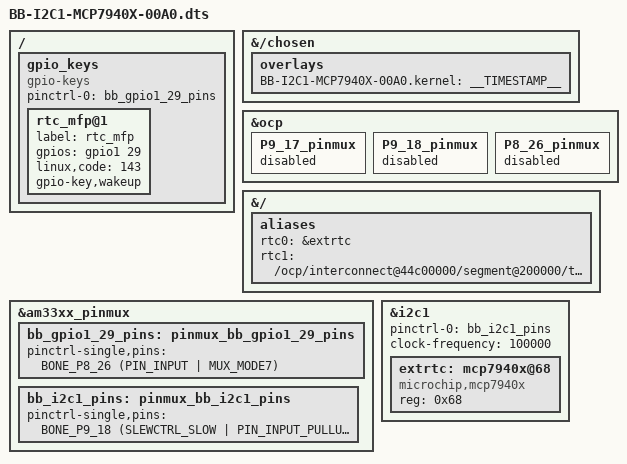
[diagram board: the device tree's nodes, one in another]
// SPDX-License-Identifier: GPL-2.0-only
/*
 * Copyright (C) 2015 Robert Nelson <robertcnelson@gmail.com>
 */

/dts-v1/;
/plugin/;

#include <dt-bindings/board/am335x-bbw-bbb-base.h>
#include <dt-bindings/pinctrl/am33xx.h>
#include <dt-bindings/gpio/gpio.h>

/*
 * Helper to show loaded overlays under: /proc/device-tree/chosen/overlays/
 */
&{/chosen} {
	overlays {
		BB-I2C1-MCP7940X-00A0.kernel = __TIMESTAMP__;
	};
};

/*
 * Free up the pins used by the cape from the pinmux helpers.
 */
&ocp {
	P9_17_pinmux { status = "disabled"; };	/* spi0_d1.i2c1_sda */
	P9_18_pinmux { status = "disabled"; };	/* spi0_cs0.i2c1_scl */
	P8_26_pinmux { status = "disabled"; };	/* rtc: gpio1_29 */
};

&{/} {
	aliases {
		rtc0 = &extrtc;
		/* find /sys/firmware/devicetree/ | grep rtc@ */
		rtc1 = "/ocp/interconnect@44c00000/segment@200000/target-module@3e000/rtc@0";
	};
};

/ {
	fragment@3 {
		target = <&am33xx_pinmux>;
		__overlay__ {

			bb_gpio1_29_pins: pinmux_bb_gpio1_29_pins {
				pinctrl-single,pins = <
					BONE_P8_26 (PIN_INPUT | MUX_MODE7) /* gpmc_csn0.gpio1_29 */
				>;
			};

			bb_i2c1_pins: pinmux_bb_i2c1_pins {
				pinctrl-single,pins = <
					BONE_P9_18 (SLEWCTRL_SLOW | PIN_INPUT_PULLUP | MUX_MODE2) /* spi0_d1.i2c1_sda */
					BONE_P9_17 (SLEWCTRL_SLOW | PIN_INPUT_PULLUP | MUX_MODE2) /* spi0_cs0.i2c1_scl */
				>;
			};
		};
	};

	fragment@4 {
		target-path="/";
		__overlay__ {

			gpio_keys {
				compatible = "gpio-keys";
				pinctrl-names = "default";
				pinctrl-0 = <&bb_gpio1_29_pins>;

				rtc_mfp@1 {
					label = "rtc_mfp";
					gpios = <&gpio1 29 GPIO_ACTIVE_HIGH>;
					linux,code = <143>; /* System Wake Up */
					gpio-key,wakeup;
				};
			};
		};
	};

	fragment@5 {
		target = <&i2c1>;
		__overlay__ {
			status = "okay";
			pinctrl-names = "default";
			pinctrl-0 = <&bb_i2c1_pins>;

			/* this is the configuration part */
			clock-frequency = <100000>;

			#address-cells = <1>;
			#size-cells = <0>;

			extrtc: mcp7940x@68 {
				compatible = "microchip,mcp7940x";
				reg = <0x68>;
			};
		};
	};
};
